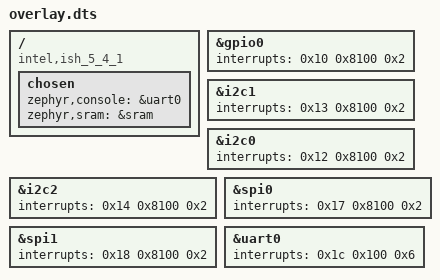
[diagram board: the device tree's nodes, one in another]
/ {
	compatible = "intel,ish_5_4_1";
	chosen {
		zephyr,console = &uart0;
		zephyr,sram = &sram;
	};
};
&gpio0{
	interrupts = < 0x10 0x8100 0x2 >;
};
&i2c1{
	interrupts = < 0x13 0x8100 0x2 >;
};
&i2c0{
	interrupts = < 0x12 0x8100 0x2 >;
};
&i2c2{
	interrupts = < 0x14 0x8100 0x2 >;
};
&spi0{
	interrupts = < 0x17 0x8100 0x2 >;
};
&spi1{
	interrupts = < 0x18 0x8100 0x2 >;
};
&uart0{
	interrupts = < 0x1c 0x100 0x6 >;
};
